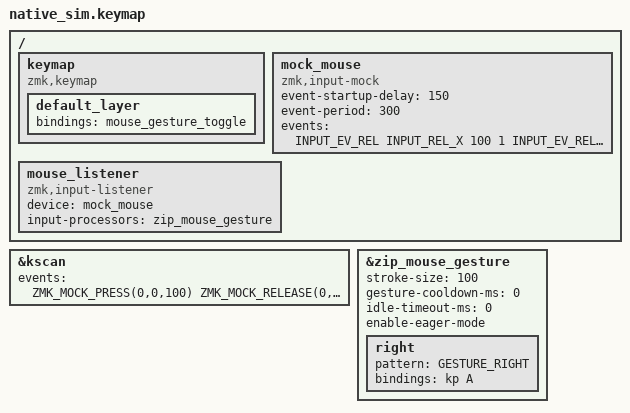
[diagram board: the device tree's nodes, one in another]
#include "../../behavior_keymap.dtsi"

/ {
    keymap {
        compatible = "zmk,keymap";
        default_layer {
            bindings = <&mouse_gesture_toggle>;
        };
    };

    mock_mouse: mock_mouse {
        compatible = "zmk,input-mock";
        event-startup-delay = <150>;
        event-period = <300>;
        events = <
            INPUT_EV_REL INPUT_REL_X 100 1
            INPUT_EV_REL INPUT_REL_X 100 1
            INPUT_EV_REL INPUT_REL_X 100 1
        >;
    };

    mouse_listener: mouse_listener {
        compatible = "zmk,input-listener";
        device = <&mock_mouse>;
        input-processors = <&zip_mouse_gesture>;
    };
};

&kscan {
    events = <
        ZMK_MOCK_PRESS(0,0,100)
        ZMK_MOCK_RELEASE(0,0,10)
        ZMK_MOCK_PRESS(0,0,300)
        ZMK_MOCK_RELEASE(0,0,10)
        ZMK_MOCK_PRESS(0,0,300)
        ZMK_MOCK_RELEASE(0,0,10)
    >;
};

&zip_mouse_gesture {
    stroke-size = <100>;
    gesture-cooldown-ms = <0>;
    idle-timeout-ms = <0>;
    enable-eager-mode;

    right {
        pattern = <GESTURE_RIGHT>;
        bindings = <&kp A>;
    };
};
